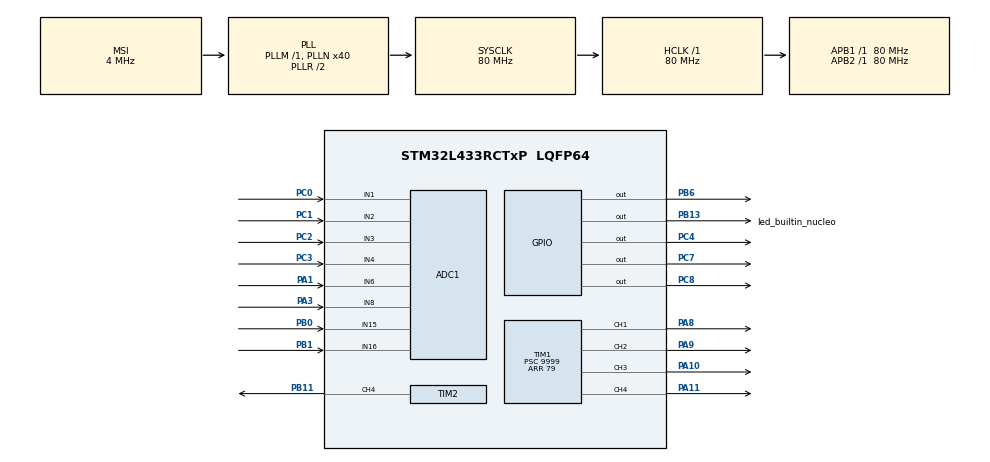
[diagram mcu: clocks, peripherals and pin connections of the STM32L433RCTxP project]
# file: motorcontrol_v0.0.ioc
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ADC1.Channel-0\#ChannelRegularConversion=ADC_CHANNEL_1
ADC1.Channel-1\#ChannelRegularConversion=ADC_CHANNEL_1
ADC1.Channel-2\#ChannelRegularConversion=ADC_CHANNEL_1
ADC1.Channel-3\#ChannelRegularConversion=ADC_CHANNEL_1
ADC1.Channel-4\#ChannelRegularConversion=ADC_CHANNEL_6
ADC1.Channel-5\#ChannelRegularConversion=ADC_CHANNEL_8
ADC1.Channel-6\#ChannelRegularConversion=ADC_CHANNEL_16
ADC1.Channel-7\#ChannelRegularConversion=ADC_CHANNEL_15
ADC1.ClockPrescaler=ADC_CLOCK_SYNC_PCLK_DIV1
ADC1.ContinuousConvMode=DISABLE
ADC1.DMAContinuousRequests=ENABLE
ADC1.EOCSelection=ADC_EOC_SEQ_CONV
ADC1.ExternalTrigConv=ADC_EXTERNALTRIG_T1_TRGO2
ADC1.NbrOfConversion=8
ADC1.NbrOfConversionFlag=1
ADC1.OffsetNumber-0\#ChannelRegularConversion=ADC_OFFSET_NONE
ADC1.OffsetNumber-1\#ChannelRegularConversion=ADC_OFFSET_NONE
ADC1.OffsetNumber-2\#ChannelRegularConversion=ADC_OFFSET_NONE
ADC1.OffsetNumber-3\#ChannelRegularConversion=ADC_OFFSET_NONE
ADC1.OffsetNumber-4\#ChannelRegularConversion=ADC_OFFSET_NONE
ADC1.OffsetNumber-5\#ChannelRegularConversion=ADC_OFFSET_NONE
ADC1.OffsetNumber-6\#ChannelRegularConversion=ADC_OFFSET_NONE
ADC1.OffsetNumber-7\#ChannelRegularConversion=ADC_OFFSET_NONE
ADC1.Overrun=ADC_OVR_DATA_OVERWRITTEN
ADC1.Rank-0\#ChannelRegularConversion=1
ADC1.Rank-1\#ChannelRegularConversion=2
ADC1.Rank-2\#ChannelRegularConversion=3
ADC1.Rank-3\#ChannelRegularConversion=4
ADC1.Rank-4\#ChannelRegularConversion=5
ADC1.Rank-5\#ChannelRegularConversion=6
ADC1.Rank-6\#ChannelRegularConversion=7
ADC1.Rank-7\#ChannelRegularConversion=8
ADC1.SamplingTime-0\#ChannelRegularConversion=ADC_SAMPLETIME_6CYCLES_5
ADC1.SamplingTime-1\#ChannelRegularConversion=ADC_SAMPLETIME_6CYCLES_5
ADC1.SamplingTime-2\#ChannelRegularConversion=ADC_SAMPLETIME_6CYCLES_5
ADC1.SamplingTime-3\#ChannelRegularConversion=ADC_SAMPLETIME_6CYCLES_5
ADC1.SamplingTime-4\#ChannelRegularConversion=ADC_SAMPLETIME_6CYCLES_5
ADC1.SamplingTime-5\#ChannelRegularConversion=ADC_SAMPLETIME_6CYCLES_5
ADC1.SamplingTime-6\#ChannelRegularConversion=ADC_SAMPLETIME_6CYCLES_5
ADC1.SamplingTime-7\#ChannelRegularConversion=ADC_SAMPLETIME_6CYCLES_5
ADC1.master=1
Dma.ADC1.0.Direction=DMA_PERIPH_TO_MEMORY
Dma.ADC1.0.Instance=DMA1_Channel1
Dma.ADC1.0.MemDataAlignment=DMA_MDATAALIGN_HALFWORD
Dma.ADC1.0.MemInc=DMA_MINC_ENABLE
Dma.ADC1.0.Mode=DMA_CIRCULAR
Dma.ADC1.0.PeriphDataAlignment=DMA_PDATAALIGN_HALFWORD
Dma.ADC1.0.PeriphInc=DMA_PINC_DISABLE
Dma.ADC1.0.Priority=DMA_PRIORITY_MEDIUM
Dma.Request0=ADC1
Mcu.Family=STM32L4
Mcu.Name=STM32L433RCTxP
Mcu.Package=LQFP64
NVIC.DMA1_Channel1_IRQn=true\:2\:0\:true\:false\:true\:false\:true\:true
NVIC.PriorityGroup=NVIC_PRIORITYGROUP_4
NVIC.TIM1_CC_IRQn=true\:5\:0\:true\:false\:true\:true\:true\:true
NVIC.TIM2_IRQn=true\:3\:0\:true\:false\:true\:true\:true\:true
PA1.Signal=ADCx_IN6
PA10.Signal=S_TIM1_CH3
PA11.Signal=S_TIM1_CH4
PA13\ (JTMS-SWDIO).Mode=Serial_Wire
PA13\ (JTMS-SWDIO).Signal=SYS_JTMS-SWDIO
PA14\ (JTCK-SWCLK).Mode=Serial_Wire
PA14\ (JTCK-SWCLK).Signal=SYS_JTCK-SWCLK
PA3.Signal=ADCx_IN8
PA8.Signal=S_TIM1_CH1
PA9.Signal=S_TIM1_CH2
PB0.Signal=ADCx_IN15
PB1.Signal=ADCx_IN16
PB11.Signal=S_TIM2_CH4
PB13.GPIO_Label=led_builtin_nucleo
PB13.Signal=GPIO_Output
PB6.Signal=GPIO_Output
PC0.Signal=ADCx_IN1
PC1.Signal=ADCx_IN2
PC2.Signal=ADCx_IN3
PC3.Signal=ADCx_IN4
PC4.GPIO_ModeDefaultOutputPP=GPIO_MODE_OUTPUT_OD
PC4.GPIO_PuPd=GPIO_PULLUP
PC4.Signal=GPIO_Output
PC7.Signal=GPIO_Output
PC8.Signal=GPIO_Output
ProjectManager.HeapSize=0x200
ProjectManager.StackSize=0x400
ProjectManager.TargetToolchain=Makefile
RCC.ADCCLockSelection=RCC_ADCCLKSOURCE_SYSCLK
RCC.ADCFreq_Value=80000000
RCC.AHBFreq_Value=80000000
RCC.APB1Freq_Value=80000000
RCC.APB1TimFreq_Value=80000000
RCC.APB2Freq_Value=80000000
RCC.APB2TimFreq_Value=80000000
RCC.CortexFreq_Value=80000000
RCC.HCLKFreq_Value=80000000
RCC.HSE_VALUE=8000000
RCC.HSI48_VALUE=48000000
RCC.HSI_VALUE=16000000
RCC.LSE_VALUE=32768
RCC.MSI_VALUE=4000000
RCC.PLLN=40
RCC.PLLSAI1N=16
RCC.SYSCLKFreq_VALUE=80000000
RCC.SYSCLKSource=RCC_SYSCLKSOURCE_PLLCLK
RCC.USBFreq_Value=32000000
RCC.VCOOutputFreq_Value=160000000
SH.ADCx_IN1.0=ADC1_IN1,IN1-Single-Ended
SH.ADCx_IN15.0=ADC1_IN15,IN15-Single-Ended
SH.ADCx_IN16.0=ADC1_IN16,IN16-Single-Ended
SH.ADCx_IN2.0=ADC1_IN2,IN2-Single-Ended
SH.ADCx_IN3.0=ADC1_IN3,IN3-Single-Ended
SH.ADCx_IN4.0=ADC1_IN4,IN4-Single-Ended
SH.ADCx_IN6.0=ADC1_IN6,IN6-Single-Ended
SH.ADCx_IN8.0=ADC1_IN8,IN8-Single-Ended
SH.S_TIM1_CH1.0=TIM1_CH1,PWM Generation1 CH1
SH.S_TIM1_CH2.0=TIM1_CH2,PWM Generation2 CH2
SH.S_TIM1_CH3.0=TIM1_CH3,PWM Generation3 CH3
SH.S_TIM1_CH4.0=TIM1_CH4,Output Compare4 CH4
SH.S_TIM2_CH4.0=TIM2_CH4,Output Compare4 CH4
TIM1.Channel-Output\ Compare4\ CH4=TIM_CHANNEL_4
TIM1.Channel-PWM\ Generation1\ CH1=TIM_CHANNEL_1
TIM1.Channel-PWM\ Generation2\ CH2=TIM_CHANNEL_2
TIM1.Channel-PWM\ Generation3\ CH3=TIM_CHANNEL_3
TIM1.CounterMode=TIM_COUNTERMODE_CENTERALIGNED1
TIM1.OCMode_4=TIM_OCMODE_TOGGLE
TIM1.Period=79
TIM1.Prescaler=9999
TIM1.TIM_MasterOutputTrigger2=TIM_TRGO2_OC4REF
TIM2.Channel-Output\ Compare4\ CH4=TIM_CHANNEL_4
TIM2.OCMode_4=TIM_OCMODE_TOGGLE
TIM2.Period=7999
TIM2.Prescaler=9999
VP_TIM1_VS_ClockSourceINT.Mode=Internal
VP_TIM2_VS_ClockSourceINT.Mode=Internal
board=custom

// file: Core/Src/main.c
/* USER CODE BEGIN Header */
/**
  ******************************************************************************
  * @file           : main.c
  * @brief          : Main program body
  ******************************************************************************
  * @attention
  *
  * Copyright (c) 2026 STMicroelectronics.
  * All rights reserved.
  *
  * This software is licensed under terms that can be found in the LICENSE file
  * in the root directory of this software component.
  * If no LICENSE file comes with this software, it is provided AS-IS.
  *
  ******************************************************************************
  */
/* USER CODE END Header */
#include "main.h"
#include "adc.h"
#include "dma.h"
#include "tim.h"
#include "gpio.h"
#include "motor.h"

void SystemClock_Config(void);

int main(void)
{

  /* MCU Configuration--------------------------------------------------------*/

  /* Reset of all peripherals, Initializes the Flash interface and the Systick. */
  HAL_Init();

  /* Configure the system clock */
  SystemClock_Config();

  /* Initialize all configured peripherals */
  MX_GPIO_Init();
  MX_DMA_Init();
  MX_TIM2_Init();
  MX_ADC1_Init();
  MX_TIM1_Init();
  /* USER CODE BEGIN 2 */
  motor_start();
  /* USER CODE END 2 */

  /* Infinite loop */
  while (1)
  {

  }
}

void SystemClock_Config(void)
{
  RCC_OscInitTypeDef RCC_OscInitStruct = {0};
  RCC_ClkInitTypeDef RCC_ClkInitStruct = {0};

  /** Configure the main internal regulator output voltage
  */
  if (HAL_PWREx_ControlVoltageScaling(PWR_REGULATOR_VOLTAGE_SCALE1) != HAL_OK)
  {
    Error_Handler();
  }

  /** Initializes the RCC Oscillators according to the specified parameters
  * in the RCC_OscInitTypeDef structure.
  */
  RCC_OscInitStruct.OscillatorType = RCC_OSCILLATORTYPE_MSI;
  RCC_OscInitStruct.MSIState = RCC_MSI_ON;
  RCC_OscInitStruct.MSICalibrationValue = 0;
  RCC_OscInitStruct.MSIClockRange = RCC_MSIRANGE_6;
  RCC_OscInitStruct.PLL.PLLState = RCC_PLL_ON;
  RCC_OscInitStruct.PLL.PLLSource = RCC_PLLSOURCE_MSI;
  RCC_OscInitStruct.PLL.PLLM = 1;
  RCC_OscInitStruct.PLL.PLLN = 40;
  RCC_OscInitStruct.PLL.PLLP = RCC_PLLP_DIV7;
  RCC_OscInitStruct.PLL.PLLQ = RCC_PLLQ_DIV2;
  RCC_OscInitStruct.PLL.PLLR = RCC_PLLR_DIV2;
  if (HAL_RCC_OscConfig(&RCC_OscInitStruct) != HAL_OK)
  {
    Error_Handler();
  }

  /** Initializes the CPU, AHB and APB buses clocks
  */
  RCC_ClkInitStruct.ClockType = RCC_CLOCKTYPE_HCLK|RCC_CLOCKTYPE_SYSCLK
                              |RCC_CLOCKTYPE_PCLK1|RCC_CLOCKTYPE_PCLK2;
  RCC_ClkInitStruct.SYSCLKSource = RCC_SYSCLKSOURCE_PLLCLK;
  RCC_ClkInitStruct.AHBCLKDivider = RCC_SYSCLK_DIV1;
  RCC_ClkInitStruct.APB1CLKDivider = RCC_HCLK_DIV1;
  RCC_ClkInitStruct.APB2CLKDivider = RCC_HCLK_DIV1;

  if (HAL_RCC_ClockConfig(&RCC_ClkInitStruct, FLASH_LATENCY_4) != HAL_OK)
  {
    Error_Handler();
  }
}

void Error_Handler(void)
{
  __disable_irq();
  while (1)
  {
  }
}
